# cslr_rac_data register map
Vendor: Texas Instruments
Peripheral module from a debugger description file.
Registers are 32-bit, read-write, reset 0x0 unless marked. A register's access mark holds for its fields unless they carry their own. Offsets are as the file gives them; lines under a group give offsets from that group; [hi:lo] are bit positions; {n}, {i} and the like mark numbered series; 'fields as' and 'values as' point back to an identical list; <NAME> marks a mode.

## RAC_DATA — Uplink Chip-Rate Decoder Co-Processor Data Space
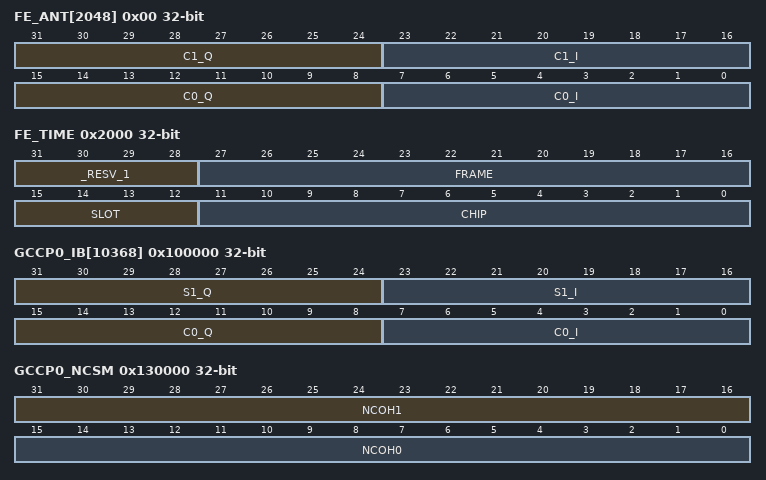
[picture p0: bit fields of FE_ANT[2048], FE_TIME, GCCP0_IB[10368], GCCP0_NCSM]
0x00 FE_ANT[2048] — Front End Antenna Input
  [31:24] C1_Q — Chip #1 Q part
  [23:16] C1_I — Chip #1 I part
  [15:8] C0_Q — Chip #0 Q part
  [7:0] C0_I — Chip #0 I part
{0x0+8i} GCCP0_CSM[{i}] (i=0..16383) group — GCCP#0 Coherent Scratch Memory
  0x00 COH_I — Coherent Scratch Element I part
    [19:0] I_PART — Coherent Element (I part)
  0x04 COH_Q — Coherent Scratch Element Q part
    [19:0] Q_PART — Coherent Element (Q part)
{0x0+8i} GCCP1_CSM[{i}] (i=0..16383) group — GCCP#1 Coherent Scratch Memory
  0x00 COH_I — Coherent Scratch Element I part
    [19:0] I_PART — Coherent Element (I part)
  0x04 COH_Q — Coherent Scratch Element Q part
    [19:0] Q_PART — Coherent Element (Q part)
0x2000 FE_TIME access not given — Front End Timestamp Register
  [31:28] _RESV_1 — (access N)
  [27:16] FRAME rw — Frame part
  [15:12] SLOT rw — Slot part
  [11:0] CHIP rw — Chip part
0x100000 GCCP0_IB[10368] — GCCP#0 Input Buffer
  [31:24] S1_Q — Sample #1 Q part
  [23:16] S1_I — Sample #1 I part
  [15:8] C0_Q — Sample #0 Q part
  [7:0] C0_I — Sample #0 I part
0x130000 GCCP0_NCSM — GCCP#0 Non Coherent Scratch Memory
  [31:16] NCOH1 — Non-Coherent Element 1
  [15:0] NCOH0 — Non-Coherent Element 0
0x140000 GCCP0_LDQ[8192] — GCCP#0 Low Priority Data Component
  [31:0] WORD
0x148000 GCCP0_LCQ[4096] — GCCP#0 Low Priority Control Component
  [31:0] WORD
0x14C000 GCCP0_HDQ[128] — GCCP#0 High Priority Data Component
  [31:0] WORD
0x150000 GCCP0_HCQ[512] — GCCP#0 High Priority Control Component
  [31:0] WORD
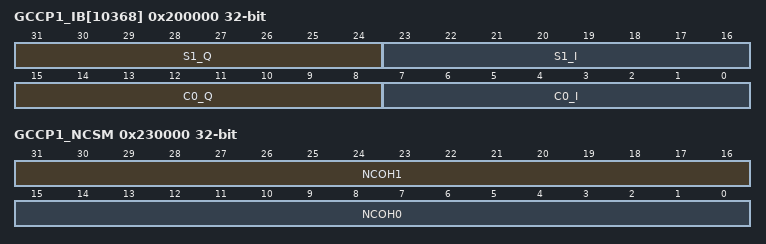
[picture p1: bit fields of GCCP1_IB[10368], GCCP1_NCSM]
0x200000 GCCP1_IB[10368] — GCCP#1 Input Buffer
  fields as GCCP0_IB[10368]
0x230000 GCCP1_NCSM — GCCP#1 Non Coherent Scratch Memory
  fields as GCCP0_NCSM
0x240000 GCCP1_LDQ[8192] — GCCP#1 Low Priority Data Component
  [31:0] WORD
0x248000 GCCP1_LCQ[4096] — GCCP#1 Low Priority Control Component
  [31:0] WORD
0x24C000 GCCP1_HDQ[128] — GCCP#1 High Priority Data Component
  [31:0] WORD
0x250000 GCCP1_HCQ[512] — GCCP#1 High Priority Control Component
  [31:0] WORD
